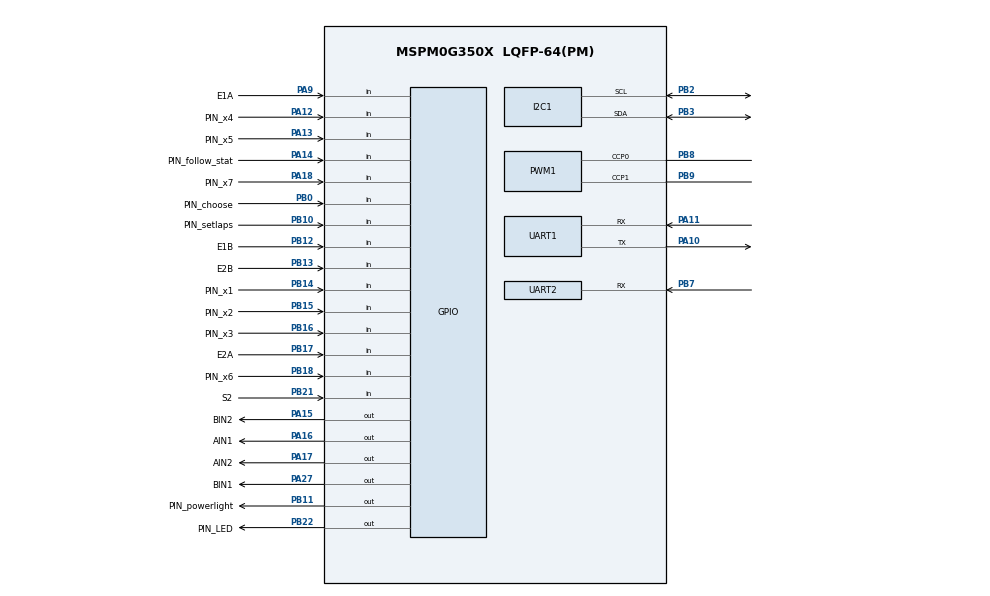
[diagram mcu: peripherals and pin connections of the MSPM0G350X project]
/**
 * @cliArgs --device "MSPM0G350X" --part "Default" --package "LQFP-64(PM)" --product "mspm0_sdk@2.05.01.01"
 * @versions {"tool":"1.24.0+4110"}
 */

/**
 * Import the modules used in this configuration.
 */
const GPIO   = scripting.addModule("/ti/driverlib/GPIO", {}, false);
const GPIO1  = GPIO.addInstance();
const GPIO2  = GPIO.addInstance();
const GPIO3  = GPIO.addInstance();
const GPIO4  = GPIO.addInstance();
const GPIO5  = GPIO.addInstance();
const GPIO6  = GPIO.addInstance();
const GPIO7  = GPIO.addInstance();
const GPIO8  = GPIO.addInstance();
const GPIO9  = GPIO.addInstance();
const I2C    = scripting.addModule("/ti/driverlib/I2C", {}, false);
const I2C1   = I2C.addInstance();
const I2C2   = I2C.addInstance();
const PWM    = scripting.addModule("/ti/driverlib/PWM", {}, false);
const PWM1   = PWM.addInstance();
const SYSCTL = scripting.addModule("/ti/driverlib/SYSCTL");
const UART   = scripting.addModule("/ti/driverlib/UART", {}, false);
const UART1  = UART.addInstance();
const UART2  = UART.addInstance();

/**
 * Write custom configuration values to the imported modules.
 */
const divider7       = system.clockTree["PLL_PDIV"];
divider7.divideValue = 2;

const divider9       = system.clockTree["UDIV"];
divider9.divideValue = 2;

const multiplier2         = system.clockTree["PLL_QDIV"];
multiplier2.multiplyValue = 5;

const mux8       = system.clockTree["HSCLKMUX"];
mux8.inputSelect = "HSCLKMUX_SYSPLL2X";

GPIO1.$name                              = "AIN";
GPIO1.associatedPins.create(2);
GPIO1.associatedPins[0].$name            = "AIN1";
GPIO1.associatedPins[0].assignedPin      = "16";
GPIO1.associatedPins[0].assignedPort     = "PORTA";
GPIO1.associatedPins[0].pin.$assign      = "PA16";
GPIO1.associatedPins[1].$name            = "AIN2";
GPIO1.associatedPins[1].assignedPort     = "PORTA";
GPIO1.associatedPins[1].assignedPin      = "17";
GPIO1.associatedPins[1].internalResistor = "PULL_DOWN";
GPIO1.associatedPins[1].pin.$assign      = "PA17";

const Board = scripting.addModule("/ti/driverlib/Board", {}, false);

GPIO2.$name                          = "BIN";
GPIO2.associatedPins.create(2);
GPIO2.associatedPins[0].$name        = "BIN1";
GPIO2.associatedPins[0].assignedPin  = "27";
GPIO2.associatedPins[0].assignedPort = "PORTA";
GPIO2.associatedPins[0].pin.$assign  = "PA27";
GPIO2.associatedPins[1].$name        = "BIN2";
GPIO2.associatedPins[1].assignedPort = "PORTA";
GPIO2.associatedPins[1].assignedPin  = "15";
GPIO2.associatedPins[1].pin.$assign  = "PA15";

GPIO3.$name                               = "GPIO_Encoder";
GPIO3.associatedPins.create(4);
GPIO3.associatedPins[0].$name             = "E1A";
GPIO3.associatedPins[0].assignedPort      = "PORTA";
GPIO3.associatedPins[0].assignedPin       = "9";
GPIO3.associatedPins[0].direction         = "INPUT";
GPIO3.associatedPins[0].interruptEn       = true;
GPIO3.associatedPins[0].polarity          = "RISE";
GPIO3.associatedPins[0].interruptPriority = "0";
GPIO3.associatedPins[0].pin.$assign       = "PA9";
GPIO3.associatedPins[1].$name             = "E2A";
GPIO3.associatedPins[1].direction         = "INPUT";
GPIO3.associatedPins[1].interruptEn       = true;
GPIO3.associatedPins[1].assignedPort      = "PORTB";
GPIO3.associatedPins[1].assignedPin       = "17";
GPIO3.associatedPins[1].polarity          = "RISE";
GPIO3.associatedPins[1].interruptPriority = "0";
GPIO3.associatedPins[1].pin.$assign       = "PB17";
GPIO3.associatedPins[2].assignedPort      = "PORTB";
GPIO3.associatedPins[2].assignedPin       = "13";
GPIO3.associatedPins[2].direction         = "INPUT";
GPIO3.associatedPins[2].$name             = "E2B";
GPIO3.associatedPins[2].polarity          = "RISE";
GPIO3.associatedPins[2].pin.$assign       = "PB13";
GPIO3.associatedPins[3].$name             = "E1B";
GPIO3.associatedPins[3].direction         = "INPUT";
GPIO3.associatedPins[3].polarity          = "RISE";
GPIO3.associatedPins[3].pin.$assign       = "PB12";

GPIO4.$name                              = "GPIO_BUTTON";
GPIO4.associatedPins[0].$name            = "S2";
GPIO4.associatedPins[0].internalResistor = "PULL_UP";
GPIO4.associatedPins[0].assignedPort     = "PORTB";
GPIO4.associatedPins[0].assignedPin      = "21";
GPIO4.associatedPins[0].direction        = "INPUT";
GPIO4.associatedPins[0].pin.$assign      = "PB21";

GPIO5.$name                          = "GPIO_TB6612";
GPIO5.associatedPins[0].$name        = "PIN_STBY";
GPIO5.associatedPins[0].assignedPort = "PORTB";
GPIO5.associatedPins[0].assignedPin  = "1";

GPIO6.$name                          = "GPIO_LED_TEST";
GPIO6.associatedPins[0].$name        = "PIN_LED";
GPIO6.associatedPins[0].assignedPin  = "22";
GPIO6.associatedPins[0].assignedPort = "PORTB";
GPIO6.associatedPins[0].pin.$assign  = "PB22";

GPIO7.$name                         = "GPIO_follow";
GPIO7.associatedPins.create(7);
GPIO7.associatedPins[0].$name       = "PIN_x1";
GPIO7.associatedPins[0].direction   = "INPUT";
GPIO7.associatedPins[0].pin.$assign = "PB14";
GPIO7.associatedPins[1].direction   = "INPUT";
GPIO7.associatedPins[1].$name       = "PIN_x2";
GPIO7.associatedPins[1].pin.$assign = "PB15";
GPIO7.associatedPins[2].$name       = "PIN_x3";
GPIO7.associatedPins[2].direction   = "INPUT";
GPIO7.associatedPins[2].pin.$assign = "PB16";
GPIO7.associatedPins[3].$name       = "PIN_x4";
GPIO7.associatedPins[3].direction   = "INPUT";
GPIO7.associatedPins[3].pin.$assign = "PA12";
GPIO7.associatedPins[4].$name       = "PIN_x5";
GPIO7.associatedPins[4].direction   = "INPUT";
GPIO7.associatedPins[4].pin.$assign = "PA13";
GPIO7.associatedPins[5].$name       = "PIN_x6";
GPIO7.associatedPins[5].direction   = "INPUT";
GPIO7.associatedPins[5].pin.$assign = "PB18";
GPIO7.associatedPins[6].$name       = "PIN_x7";
GPIO7.associatedPins[6].direction   = "INPUT";
GPIO7.associatedPins[6].pin.$assign = "PA18";

GPIO8.$name                         = "GPIO_powerlight";
GPIO8.associatedPins[0].$name       = "PIN_powerlight";
GPIO8.associatedPins[0].pin.$assign = "PB11";

GPIO9.$name                              = "GPIO_ControlKey";
GPIO9.associatedPins.create(3);
GPIO9.associatedPins[0].$name            = "PIN_choose";
GPIO9.associatedPins[0].direction        = "INPUT";
GPIO9.associatedPins[0].internalResistor = "PULL_UP";
GPIO9.associatedPins[0].pin.$assign      = "PB0";
GPIO9.associatedPins[1].$name            = "PIN_setlaps";
GPIO9.associatedPins[1].direction        = "INPUT";
GPIO9.associatedPins[1].internalResistor = "PULL_UP";
GPIO9.associatedPins[1].pin.$assign      = "PB10";
GPIO9.associatedPins[2].direction        = "INPUT";
GPIO9.associatedPins[2].internalResistor = "PULL_UP";
GPIO9.associatedPins[2].$name            = "PIN_follow_stat";
GPIO9.associatedPins[2].pin.$assign      = "PA14";

I2C1.$name                             = "I2C_MPU6050";
I2C1.basicEnableController             = true;
I2C1.basicControllerStandardBusSpeed   = "Fast";
I2C1.peripheral.sdaPin.$assign         = "PB3";
I2C1.peripheral.sclPin.$assign         = "PB2";
I2C1.sdaPinConfig.$name                = "ti_driverlib_gpio_GPIOPinGeneric0";
I2C1.sdaPinConfig.hideOutputInversion  = scripting.forceWrite(false);
I2C1.sdaPinConfig.onlyInternalResistor = scripting.forceWrite(false);
I2C1.sdaPinConfig.passedPeripheralType = scripting.forceWrite("Digital");
I2C1.sclPinConfig.$name                = "ti_driverlib_gpio_GPIOPinGeneric1";
I2C1.sclPinConfig.hideOutputInversion  = scripting.forceWrite(false);
I2C1.sclPinConfig.onlyInternalResistor = scripting.forceWrite(false);
I2C1.sclPinConfig.passedPeripheralType = scripting.forceWrite("Digital");

I2C2.basicEnableController             = true;
I2C2.basicControllerStandardBusSpeed   = "Fast";
I2C2.$name                             = "I2C_OLED";
I2C2.sdaPinConfig.hideOutputInversion  = scripting.forceWrite(false);
I2C2.sdaPinConfig.onlyInternalResistor = scripting.forceWrite(false);
I2C2.sdaPinConfig.passedPeripheralType = scripting.forceWrite("Digital");
I2C2.sdaPinConfig.$name                = "ti_driverlib_gpio_GPIOPinGeneric6";
I2C2.sclPinConfig.hideOutputInversion  = scripting.forceWrite(false);
I2C2.sclPinConfig.onlyInternalResistor = scripting.forceWrite(false);
I2C2.sclPinConfig.passedPeripheralType = scripting.forceWrite("Digital");
I2C2.sclPinConfig.$name                = "ti_driverlib_gpio_GPIOPinGeneric8";

PWM1.pwmMode                            = "EDGE_ALIGN_UP";
PWM1.$name                              = "PWM_AB";
PWM1.timerStartTimer                    = true;
PWM1.peripheral.$assign                 = "TIMA0";
PWM1.peripheral.ccp0Pin.$assign         = "PB8";
PWM1.peripheral.ccp1Pin.$assign         = "PB9";
PWM1.PWM_CHANNEL_0.$name                = "ti_driverlib_pwm_PWMTimerCC0";
PWM1.PWM_CHANNEL_1.$name                = "ti_driverlib_pwm_PWMTimerCC1";
PWM1.ccp0PinConfig.direction            = scripting.forceWrite("OUTPUT");
PWM1.ccp0PinConfig.hideOutputInversion  = scripting.forceWrite(false);
PWM1.ccp0PinConfig.onlyInternalResistor = scripting.forceWrite(false);
PWM1.ccp0PinConfig.passedPeripheralType = scripting.forceWrite("Digital");
PWM1.ccp0PinConfig.$name                = "ti_driverlib_gpio_GPIOPinGeneric2";
PWM1.ccp1PinConfig.direction            = scripting.forceWrite("OUTPUT");
PWM1.ccp1PinConfig.hideOutputInversion  = scripting.forceWrite(false);
PWM1.ccp1PinConfig.onlyInternalResistor = scripting.forceWrite(false);
PWM1.ccp1PinConfig.passedPeripheralType = scripting.forceWrite("Digital");
PWM1.ccp1PinConfig.$name                = "ti_driverlib_gpio_GPIOPinGeneric3";

SYSCTL.forceDefaultClkConfig = true;
SYSCTL.clockTreeEn           = true;
scripting.suppress("For best practices when the CPUCLK is running at 32MHz and above, clear the flash status bit using DL_FlashCTL_executeClearStatus\\(\\) before executing any flash operation\\. Otherwise there may be false positives\\.", SYSCTL);

UART1.$name                    = "UART_0";
UART1.peripheral.rxPin.$assign = "PA11";
UART1.peripheral.txPin.$assign = "PA10";
UART1.txPinConfig.$name        = "ti_driverlib_gpio_GPIOPinGeneric4";
UART1.rxPinConfig.$name        = "ti_driverlib_gpio_GPIOPinGeneric5";

UART2.targetBaudRate                   = 115200;
UART2.direction                        = "RX";
UART2.enableFIFO                       = true;
UART2.rxTimeoutValue                   = 1;
UART2.enabledInterrupts                = ["RX_TIMEOUT_ERROR"];
UART2.enabledDMARXTriggers             = "DL_UART_DMA_INTERRUPT_RX";
UART2.$name                            = "UART_BNO08X";
UART2.rxPinConfig.hideOutputInversion  = scripting.forceWrite(false);
UART2.rxPinConfig.onlyInternalResistor = scripting.forceWrite(false);
UART2.rxPinConfig.passedPeripheralType = scripting.forceWrite("Digital");
UART2.rxPinConfig.$name                = "ti_driverlib_gpio_GPIOPinGeneric7";
UART2.peripheral.$assign               = "UART1";
UART2.peripheral.rxPin.$assign         = "PB7";
UART2.DMA_CHANNEL_RX.addressMode       = "f2b";
UART2.DMA_CHANNEL_RX.srcLength         = "BYTE";
UART2.DMA_CHANNEL_RX.dstLength         = "BYTE";
UART2.DMA_CHANNEL_RX.$name             = "DMA_BNO08X";

/**
 * Pinmux solution for unlocked pins/peripherals. This ensures that minor changes to the automatic solver in a future
 * version of the tool will not impact the pinmux you originally saw.  These lines can be completely deleted in order to
 * re-solve from scratch.
 */
Board.peripheral.$suggestSolution                = "DEBUGSS";
Board.peripheral.swclkPin.$suggestSolution       = "PA20";
Board.peripheral.swdioPin.$suggestSolution       = "PA19";
GPIO5.associatedPins[0].pin.$suggestSolution     = "PB1";
I2C1.peripheral.$suggestSolution                 = "I2C1";
I2C2.peripheral.$suggestSolution                 = "I2C0";
I2C2.peripheral.sdaPin.$suggestSolution          = "PA0";
I2C2.peripheral.sclPin.$suggestSolution          = "PA1";
UART1.peripheral.$suggestSolution                = "UART0";
UART2.DMA_CHANNEL_RX.peripheral.$suggestSolution = "DMA_CH0";
